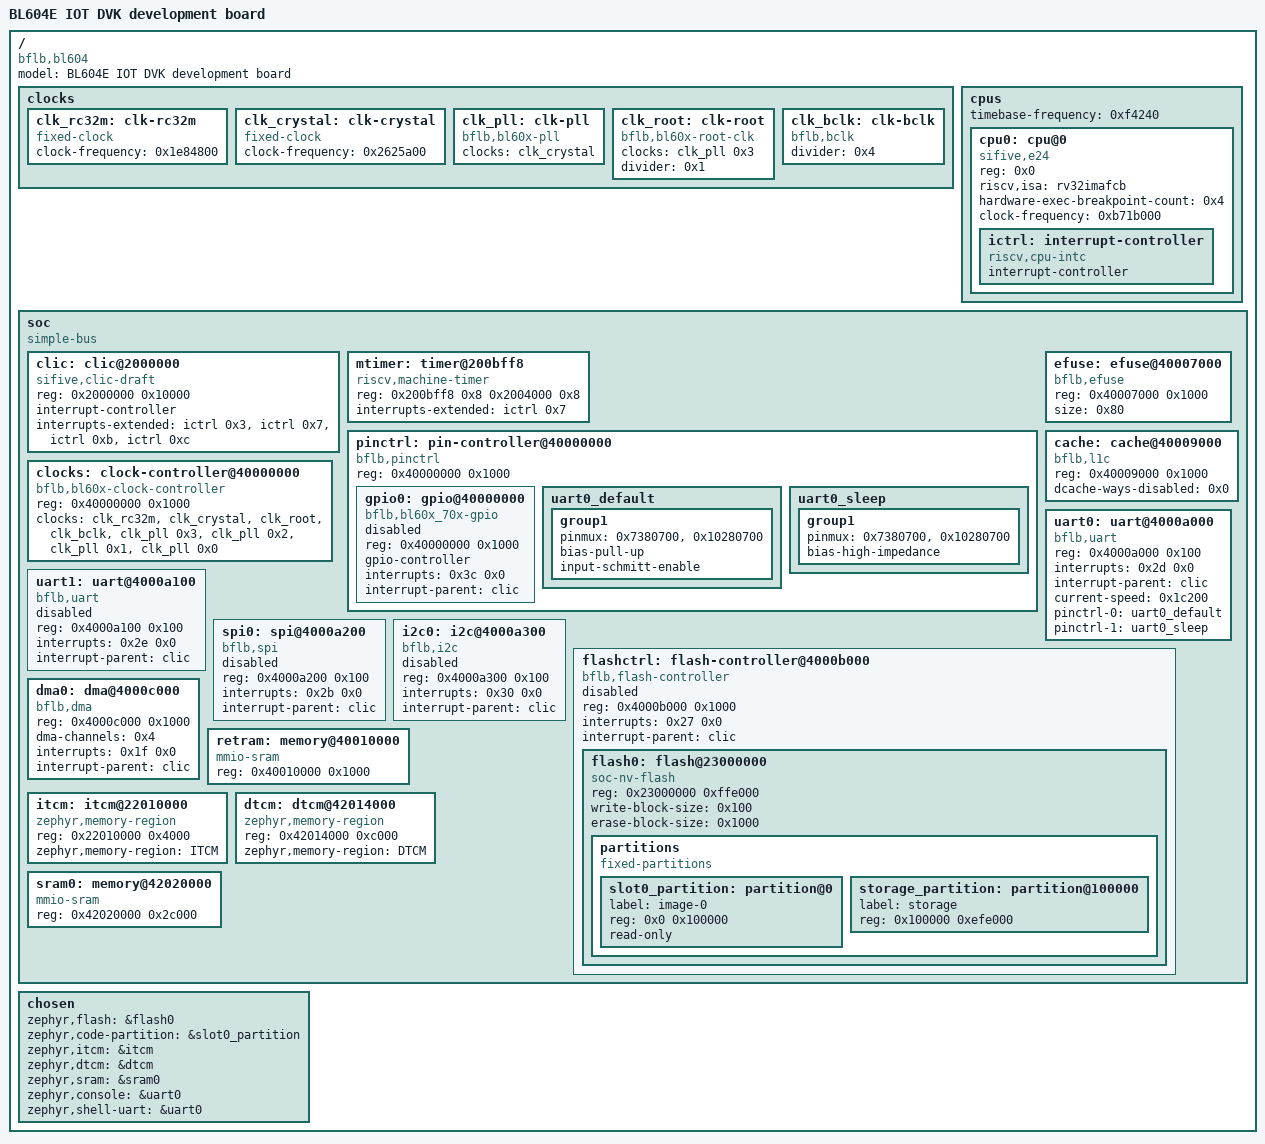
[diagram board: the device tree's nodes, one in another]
/dts-v1/;

/* node '/' defined in zephyr/dts/riscv/bflb/bl60x.dtsi:15 */
/ {
	#address-cells = < 0x1 >;                   /* in zephyr/dts/riscv/bflb/bl60x.dtsi:16 */
	#size-cells = < 0x1 >;                      /* in zephyr/dts/riscv/bflb/bl60x.dtsi:17 */
	model = "BL604E IOT DVK development board"; /* in zephyr/boards/bflb/bl60x/bl604e_iot_dvk/bl604e_iot_dvk.dts:13 */
	compatible = "bflb,bl604";                  /* in zephyr/boards/bflb/bl60x/bl604e_iot_dvk/bl604e_iot_dvk.dts:14 */

	/* node '/clocks' defined in zephyr/dts/riscv/bflb/bl60x.dtsi:19 */
	clocks {

		/* node '/clocks/clk-rc32m' defined in zephyr/dts/riscv/bflb/bl60x.dtsi:20 */
		clk_rc32m: clk-rc32m {
			#clock-cells = < 0x0 >;          /* in zephyr/dts/riscv/bflb/bl60x.dtsi:21 */
			compatible = "fixed-clock";      /* in zephyr/dts/riscv/bflb/bl60x.dtsi:22 */
			clock-frequency = < 0x1e84800 >; /* in zephyr/dts/riscv/bflb/bl60x.dtsi:23 */
			status = "okay";                 /* in zephyr/dts/riscv/bflb/bl60x.dtsi:24 */
			phandle = < 0x5 >;               /* in zephyr/dts/riscv/bflb/bl60x.dtsi:132 */
		};

		/* node '/clocks/clk-crystal' defined in zephyr/dts/riscv/bflb/bl60x.dtsi:27 */
		clk_crystal: clk-crystal {
			#clock-cells = < 0x0 >;          /* in zephyr/dts/riscv/bflb/bl60x.dtsi:28 */
			compatible = "fixed-clock";      /* in zephyr/dts/riscv/bflb/bl60x.dtsi:29 */
			clock-frequency = < 0x2625a00 >; /* in zephyr/dts/riscv/bflb/bl60x.dtsi:30 */
			status = "okay";                 /* in zephyr/dts/riscv/bflb/bl60x.dtsi:31 */
			phandle = < 0x1 >;               /* in zephyr/dts/riscv/bflb/bl60x.dtsi:37 */
		};

		/* node '/clocks/clk-pll' defined in zephyr/dts/riscv/bflb/bl60x.dtsi:34 */
		clk_pll: clk-pll {
			#clock-cells = < 0x1 >;        /* in zephyr/dts/riscv/bflb/bl60x.dtsi:35 */
			compatible = "bflb,bl60x-pll"; /* in zephyr/dts/riscv/bflb/bl60x.dtsi:36 */
			clocks = < &clk_crystal >;     /* in zephyr/dts/riscv/bflb/bl60x.dtsi:37 */
			status = "okay";               /* in zephyr/dts/riscv/bflb/bl60x.dtsi:38 */
			phandle = < 0x2 >;             /* in zephyr/dts/riscv/bflb/bl60x.dtsi:44 */
		};

		/* node '/clocks/clk-root' defined in zephyr/dts/riscv/bflb/bl60x.dtsi:41 */
		clk_root: clk-root {
			#clock-cells = < 0x0 >;             /* in zephyr/dts/riscv/bflb/bl60x.dtsi:42 */
			compatible = "bflb,bl60x-root-clk"; /* in zephyr/dts/riscv/bflb/bl60x.dtsi:43 */
			clocks = < &clk_pll 0x3 >;          /* in zephyr/dts/riscv/bflb/bl60x.dtsi:44 */
			divider = < 0x1 >;                  /* in zephyr/dts/riscv/bflb/bl60x.dtsi:45 */
			status = "okay";                    /* in zephyr/dts/riscv/bflb/bl60x.dtsi:46 */
			phandle = < 0x6 >;                  /* in zephyr/dts/riscv/bflb/bl60x.dtsi:132 */
		};

		/* node '/clocks/clk-bclk' defined in zephyr/dts/riscv/bflb/bl60x.dtsi:49 */
		clk_bclk: clk-bclk {
			#clock-cells = < 0x0 >;   /* in zephyr/dts/riscv/bflb/bl60x.dtsi:50 */
			compatible = "bflb,bclk"; /* in zephyr/dts/riscv/bflb/bl60x.dtsi:51 */
			divider = < 0x4 >;        /* in zephyr/dts/riscv/bflb/bl60x.dtsi:52 */
			status = "okay";          /* in zephyr/dts/riscv/bflb/bl60x.dtsi:53 */
			phandle = < 0x7 >;        /* in zephyr/dts/riscv/bflb/bl60x.dtsi:132 */
		};
	};

	/* node '/cpus' defined in zephyr/dts/riscv/bflb/bl60x.dtsi:57 */
	cpus {
		#address-cells = < 0x1 >;         /* in zephyr/dts/riscv/bflb/bl60x.dtsi:58 */
		#size-cells = < 0x0 >;            /* in zephyr/dts/riscv/bflb/bl60x.dtsi:59 */
		timebase-frequency = < 0xf4240 >; /* in zephyr/dts/riscv/bflb/bl60x.dtsi:60 */

		/* node '/cpus/cpu@0' defined in zephyr/dts/riscv/bflb/bl60x.dtsi:62 */
		cpu0: cpu@0 {
			device_type = "cpu";                      /* in zephyr/dts/riscv/bflb/bl60x.dtsi:63 */
			compatible = "sifive,e24",
			             "riscv";                     /* in zephyr/dts/riscv/bflb/bl60x.dtsi:64 */
			reg = < 0x0 >;                            /* in zephyr/dts/riscv/bflb/bl60x.dtsi:65 */
			riscv,isa = "rv32imafcb";                 /* in zephyr/dts/riscv/bflb/bl60x.dtsi:66 */
			hardware-exec-breakpoint-count = < 0x4 >; /* in zephyr/dts/riscv/bflb/bl60x.dtsi:67 */
			status = "okay";                          /* in zephyr/dts/riscv/bflb/bl60x.dtsi:68 */
			clock-frequency = < 0xb71b000 >;          /* in zephyr/boards/bflb/bl60x/bl604e_iot_dvk/bl604e_iot_dvk.dts:28 */

			/* node '/cpus/cpu@0/interrupt-controller' defined in zephyr/dts/riscv/bflb/bl60x.dtsi:70 */
			ictrl: interrupt-controller {
				#address-cells = < 0x0 >;      /* in zephyr/dts/riscv/bflb/bl60x.dtsi:71 */
				#interrupt-cells = < 0x1 >;    /* in zephyr/dts/riscv/bflb/bl60x.dtsi:72 */
				compatible = "riscv,cpu-intc"; /* in zephyr/dts/riscv/bflb/bl60x.dtsi:73 */
				interrupt-controller;          /* in zephyr/dts/riscv/bflb/bl60x.dtsi:74 */
				phandle = < 0x3 >;             /* in zephyr/dts/riscv/bflb/bl60x.dtsi:92 */
			};
		};
	};

	/* node '/soc' defined in zephyr/dts/riscv/bflb/bl60x.dtsi:79 */
	soc {
		compatible = "simple-bus"; /* in zephyr/dts/riscv/bflb/bl60x.dtsi:80 */
		#address-cells = < 0x1 >;  /* in zephyr/dts/riscv/bflb/bl60x.dtsi:81 */
		#size-cells = < 0x1 >;     /* in zephyr/dts/riscv/bflb/bl60x.dtsi:82 */
		ranges;                    /* in zephyr/dts/riscv/bflb/bl60x.dtsi:83 */

		/* node '/soc/clic@2000000' defined in zephyr/dts/riscv/bflb/bl60x.dtsi:85 */
		clic: clic@2000000 {
			compatible = "sifive,clic-draft";                                      /* in zephyr/dts/riscv/bflb/bl60x.dtsi:86 */
			reg = < 0x2000000 0x10000 >;                                           /* in zephyr/dts/riscv/bflb/bl60x.dtsi:87 */
			#address-cells = < 0x0 >;                                              /* in zephyr/dts/riscv/bflb/bl60x.dtsi:88 */
			#interrupt-cells = < 0x2 >;                                            /* in zephyr/dts/riscv/bflb/bl60x.dtsi:89 */
			interrupt-controller;                                                  /* in zephyr/dts/riscv/bflb/bl60x.dtsi:91 */
			interrupts-extended = < &ictrl 0x3 &ictrl 0x7 &ictrl 0xb &ictrl 0xc >; /* in zephyr/dts/riscv/bflb/bl60x.dtsi:92 */
			interrupt-names = "msip",
			                  "mtip",
			                  "meip",
			                  "csip";                                              /* in zephyr/dts/riscv/bflb/bl60x.dtsi:93 */
			phandle = < 0x4 >;                                                     /* in zephyr/dts/riscv/bflb/bl60x.dtsi:123 */
		};

		/* node '/soc/timer@200bff8' defined in zephyr/dts/riscv/bflb/bl60x.dtsi:99 */
		mtimer: timer@200bff8 {
			compatible = "riscv,machine-timer";    /* in zephyr/dts/riscv/bflb/bl60x.dtsi:100 */
			reg = < 0x200bff8 0x8 0x2004000 0x8 >; /* in zephyr/dts/riscv/bflb/bl60x.dtsi:101 */
			reg-names = "mtime",
			            "mtimecmp";                /* in zephyr/dts/riscv/bflb/bl60x.dtsi:102 */
			interrupts-extended = < &ictrl 0x7 >;  /* in zephyr/dts/riscv/bflb/bl60x.dtsi:104 */
		};

		/* node '/soc/pin-controller@40000000' defined in zephyr/dts/riscv/bflb/bl60x.dtsi:107 */
		pinctrl: pin-controller@40000000 {
			compatible = "bflb,pinctrl";               /* in zephyr/dts/riscv/bflb/bl60x.dtsi:108 */
			reg = < 0x40000000 0x1000 >;               /* in zephyr/dts/riscv/bflb/bl60x.dtsi:109 */
			ranges = < 0x40000000 0x40000000 0x1000 >; /* in zephyr/dts/riscv/bflb/bl60x.dtsi:110 */
			#address-cells = < 0x1 >;                  /* in zephyr/dts/riscv/bflb/bl60x.dtsi:111 */
			#size-cells = < 0x1 >;                     /* in zephyr/dts/riscv/bflb/bl60x.dtsi:112 */
			status = "okay";                           /* in zephyr/dts/riscv/bflb/bl60x.dtsi:113 */

			/* node '/soc/pin-controller@40000000/gpio@40000000' defined in zephyr/dts/riscv/bflb/bl60x.dtsi:115 */
			gpio0: gpio@40000000 {
				compatible = "bflb,bl60x_70x-gpio"; /* in zephyr/dts/riscv/bflb/bl60x.dtsi:116 */
				reg = < 0x40000000 0x1000 >;        /* in zephyr/dts/riscv/bflb/bl60x.dtsi:117 */
				#gpio-cells = < 0x2 >;              /* in zephyr/dts/riscv/bflb/bl60x.dtsi:118 */
				status = "disabled";                /* in zephyr/dts/riscv/bflb/bl60x.dtsi:119 */
				gpio-controller;                    /* in zephyr/dts/riscv/bflb/bl60x.dtsi:121 */
				interrupts = < 0x3c 0x0 >;          /* in zephyr/dts/riscv/bflb/bl60x.dtsi:122 */
				interrupt-parent = < &clic >;       /* in zephyr/dts/riscv/bflb/bl60x.dtsi:123 */
			};

			/* node '/soc/pin-controller@40000000/uart0_default' defined in zephyr/boards/bflb/bl60x/bl604e_iot_dvk/bl604e_iot_dvk-pinctrl.dtsi:10 */
			uart0_default: uart0_default {
				phandle = < 0x8 >; /* in zephyr/boards/bflb/bl60x/bl604e_iot_dvk/bl604e_iot_dvk.dts:62 */

				/* node '/soc/pin-controller@40000000/uart0_default/group1' defined in zephyr/boards/bflb/bl60x/bl604e_iot_dvk/bl604e_iot_dvk-pinctrl.dtsi:11 */
				group1 {
					pinmux = < 0x7380700 >,
					         < 0x10280700 >; /* in zephyr/boards/bflb/bl60x/bl604e_iot_dvk/bl604e_iot_dvk-pinctrl.dtsi:12 */
					bias-pull-up;            /* in zephyr/boards/bflb/bl60x/bl604e_iot_dvk/bl604e_iot_dvk-pinctrl.dtsi:14 */
					input-schmitt-enable;    /* in zephyr/boards/bflb/bl60x/bl604e_iot_dvk/bl604e_iot_dvk-pinctrl.dtsi:15 */
				};
			};

			/* node '/soc/pin-controller@40000000/uart0_sleep' defined in zephyr/boards/bflb/bl60x/bl604e_iot_dvk/bl604e_iot_dvk-pinctrl.dtsi:19 */
			uart0_sleep: uart0_sleep {
				phandle = < 0x9 >; /* in zephyr/boards/bflb/bl60x/bl604e_iot_dvk/bl604e_iot_dvk.dts:63 */

				/* node '/soc/pin-controller@40000000/uart0_sleep/group1' defined in zephyr/boards/bflb/bl60x/bl604e_iot_dvk/bl604e_iot_dvk-pinctrl.dtsi:20 */
				group1 {
					pinmux = < 0x7380700 >,
					         < 0x10280700 >; /* in zephyr/boards/bflb/bl60x/bl604e_iot_dvk/bl604e_iot_dvk-pinctrl.dtsi:21 */
					bias-high-impedance;     /* in zephyr/boards/bflb/bl60x/bl604e_iot_dvk/bl604e_iot_dvk-pinctrl.dtsi:23 */
				};
			};
		};

		/* node '/soc/clock-controller@40000000' defined in zephyr/dts/riscv/bflb/bl60x.dtsi:127 */
		clocks: clock-controller@40000000 {
			compatible = "bflb,bl60x-clock-controller",
			             "bflb,clock-controller";       /* in zephyr/dts/riscv/bflb/bl60x.dtsi:128 */
			reg = < 0x40000000 0x1000 >;                /* in zephyr/dts/riscv/bflb/bl60x.dtsi:129 */
			#clock-cells = < 0x1 >;                     /* in zephyr/dts/riscv/bflb/bl60x.dtsi:130 */
			status = "okay";                            /* in zephyr/dts/riscv/bflb/bl60x.dtsi:131 */
			clocks = < &clk_rc32m >,
			         < &clk_crystal >,
			         < &clk_root >,
			         < &clk_bclk >,
			         < &clk_pll 0x3 >,
			         < &clk_pll 0x2 >,
			         < &clk_pll 0x1 >,
			         < &clk_pll 0x0 >;                  /* in zephyr/dts/riscv/bflb/bl60x.dtsi:132 */
			clock-names = "rc32m",
			              "crystal",
			              "root",
			              "bclk",
			              "pll_192",
			              "pll_160",
			              "pll_120",
			              "pll_48";                     /* in zephyr/dts/riscv/bflb/bl60x.dtsi:135 */
		};

		/* node '/soc/efuse@40007000' defined in zephyr/dts/riscv/bflb/bl60x.dtsi:140 */
		efuse: efuse@40007000 {
			compatible = "bflb,efuse";   /* in zephyr/dts/riscv/bflb/bl60x.dtsi:141 */
			reg = < 0x40007000 0x1000 >; /* in zephyr/dts/riscv/bflb/bl60x.dtsi:142 */
			status = "okay";             /* in zephyr/dts/riscv/bflb/bl60x.dtsi:143 */
			size = < 0x80 >;             /* in zephyr/dts/riscv/bflb/bl60x.dtsi:144 */
		};

		/* node '/soc/cache@40009000' defined in zephyr/dts/riscv/bflb/bl60x.dtsi:147 */
		cache: cache@40009000 {
			reg = < 0x40009000 0x1000 >;    /* in zephyr/dts/riscv/bflb/bl60x.dtsi:148 */
			compatible = "bflb,l1c";        /* in zephyr/dts/riscv/bflb/bl60x.dtsi:149 */
			dcache-ways-disabled = < 0x0 >; /* in zephyr/dts/riscv/bflb/bl60x.dtsi:150 */
		};

		/* node '/soc/uart@4000a000' defined in zephyr/dts/riscv/bflb/bl60x.dtsi:153 */
		uart0: uart@4000a000 {
			compatible = "bflb,uart";       /* in zephyr/dts/riscv/bflb/bl60x.dtsi:154 */
			reg = < 0x4000a000 0x100 >;     /* in zephyr/dts/riscv/bflb/bl60x.dtsi:155 */
			interrupts = < 0x2d 0x0 >;      /* in zephyr/dts/riscv/bflb/bl60x.dtsi:156 */
			interrupt-parent = < &clic >;   /* in zephyr/dts/riscv/bflb/bl60x.dtsi:157 */
			status = "okay";                /* in zephyr/boards/bflb/bl60x/bl604e_iot_dvk/bl604e_iot_dvk.dts:59 */
			current-speed = < 0x1c200 >;    /* in zephyr/boards/bflb/bl60x/bl604e_iot_dvk/bl604e_iot_dvk.dts:60 */
			pinctrl-0 = < &uart0_default >; /* in zephyr/boards/bflb/bl60x/bl604e_iot_dvk/bl604e_iot_dvk.dts:62 */
			pinctrl-1 = < &uart0_sleep >;   /* in zephyr/boards/bflb/bl60x/bl604e_iot_dvk/bl604e_iot_dvk.dts:63 */
			pinctrl-names = "default",
			                "sleep";        /* in zephyr/boards/bflb/bl60x/bl604e_iot_dvk/bl604e_iot_dvk.dts:64 */
		};

		/* node '/soc/uart@4000a100' defined in zephyr/dts/riscv/bflb/bl60x.dtsi:161 */
		uart1: uart@4000a100 {
			compatible = "bflb,uart";     /* in zephyr/dts/riscv/bflb/bl60x.dtsi:162 */
			reg = < 0x4000a100 0x100 >;   /* in zephyr/dts/riscv/bflb/bl60x.dtsi:163 */
			interrupts = < 0x2e 0x0 >;    /* in zephyr/dts/riscv/bflb/bl60x.dtsi:164 */
			interrupt-parent = < &clic >; /* in zephyr/dts/riscv/bflb/bl60x.dtsi:165 */
			status = "disabled";          /* in zephyr/dts/riscv/bflb/bl60x.dtsi:166 */
		};

		/* node '/soc/spi@4000a200' defined in zephyr/dts/riscv/bflb/bl60x.dtsi:169 */
		spi0: spi@4000a200 {
			compatible = "bflb,spi";      /* in zephyr/dts/riscv/bflb/bl60x.dtsi:170 */
			reg = < 0x4000a200 0x100 >;   /* in zephyr/dts/riscv/bflb/bl60x.dtsi:171 */
			#address-cells = < 0x1 >;     /* in zephyr/dts/riscv/bflb/bl60x.dtsi:172 */
			#size-cells = < 0x0 >;        /* in zephyr/dts/riscv/bflb/bl60x.dtsi:173 */
			status = "disabled";          /* in zephyr/dts/riscv/bflb/bl60x.dtsi:174 */
			interrupts = < 0x2b 0x0 >;    /* in zephyr/dts/riscv/bflb/bl60x.dtsi:176 */
			interrupt-parent = < &clic >; /* in zephyr/dts/riscv/bflb/bl60x.dtsi:177 */
		};

		/* node '/soc/i2c@4000a300' defined in zephyr/dts/riscv/bflb/bl60x.dtsi:180 */
		i2c0: i2c@4000a300 {
			compatible = "bflb,i2c";      /* in zephyr/dts/riscv/bflb/bl60x.dtsi:181 */
			reg = < 0x4000a300 0x100 >;   /* in zephyr/dts/riscv/bflb/bl60x.dtsi:182 */
			#address-cells = < 0x1 >;     /* in zephyr/dts/riscv/bflb/bl60x.dtsi:183 */
			#size-cells = < 0x0 >;        /* in zephyr/dts/riscv/bflb/bl60x.dtsi:184 */
			status = "disabled";          /* in zephyr/dts/riscv/bflb/bl60x.dtsi:185 */
			interrupts = < 0x30 0x0 >;    /* in zephyr/dts/riscv/bflb/bl60x.dtsi:187 */
			interrupt-parent = < &clic >; /* in zephyr/dts/riscv/bflb/bl60x.dtsi:188 */
		};

		/* node '/soc/flash-controller@4000b000' defined in zephyr/dts/riscv/bflb/bl60x.dtsi:191 */
		flashctrl: flash-controller@4000b000 {
			compatible = "bflb,flash-controller"; /* in zephyr/dts/riscv/bflb/bl60x.dtsi:192 */
			reg = < 0x4000b000 0x1000 >;          /* in zephyr/dts/riscv/bflb/bl60x.dtsi:193 */
			#address-cells = < 0x1 >;             /* in zephyr/dts/riscv/bflb/bl60x.dtsi:194 */
			#size-cells = < 0x1 >;                /* in zephyr/dts/riscv/bflb/bl60x.dtsi:195 */
			status = "disabled";                  /* in zephyr/dts/riscv/bflb/bl60x.dtsi:196 */
			interrupts = < 0x27 0x0 >;            /* in zephyr/dts/riscv/bflb/bl60x.dtsi:198 */
			interrupt-parent = < &clic >;         /* in zephyr/dts/riscv/bflb/bl60x.dtsi:199 */

			/* node '/soc/flash-controller@4000b000/flash@23000000' defined in zephyr/boards/bflb/bl60x/bl604e_iot_dvk/bl604e_iot_dvk.dts:32 */
			flash0: flash@23000000 {
				compatible = "soc-nv-flash",
				             "issi,is25lp128"; /* in zephyr/boards/bflb/bl60x/bl604e_iot_dvk/bl604e_iot_dvk.dts:33 */
				reg = < 0x23000000 0xffe000 >; /* in zephyr/boards/bflb/bl60x/bl604e_iot_dvk/bl604e_iot_dvk.dts:34 */
				write-block-size = < 0x100 >;  /* in zephyr/boards/bflb/bl60x/bl604e_iot_dvk/bl604e_iot_dvk.dts:35 */
				erase-block-size = < 0x1000 >; /* in zephyr/boards/bflb/bl60x/bl604e_iot_dvk/bl604e_iot_dvk.dts:36 */

				/* node '/soc/flash-controller@4000b000/flash@23000000/partitions' defined in zephyr/boards/bflb/bl60x/bl604e_iot_dvk/bl604e_iot_dvk.dts:39 */
				partitions {
					compatible = "fixed-partitions"; /* in zephyr/boards/bflb/bl60x/bl604e_iot_dvk/bl604e_iot_dvk.dts:40 */
					#address-cells = < 0x1 >;        /* in zephyr/boards/bflb/bl60x/bl604e_iot_dvk/bl604e_iot_dvk.dts:41 */
					#size-cells = < 0x1 >;           /* in zephyr/boards/bflb/bl60x/bl604e_iot_dvk/bl604e_iot_dvk.dts:42 */

					/* node '/soc/flash-controller@4000b000/flash@23000000/partitions/partition@0' defined in zephyr/boards/bflb/bl60x/bl604e_iot_dvk/bl604e_iot_dvk.dts:44 */
					slot0_partition: partition@0 {
						label = "image-0";      /* in zephyr/boards/bflb/bl60x/bl604e_iot_dvk/bl604e_iot_dvk.dts:45 */
						reg = < 0x0 0x100000 >; /* in zephyr/boards/bflb/bl60x/bl604e_iot_dvk/bl604e_iot_dvk.dts:46 */
						read-only;              /* in zephyr/boards/bflb/bl60x/bl604e_iot_dvk/bl604e_iot_dvk.dts:47 */
					};

					/* node '/soc/flash-controller@4000b000/flash@23000000/partitions/partition@100000' defined in zephyr/boards/bflb/bl60x/bl604e_iot_dvk/bl604e_iot_dvk.dts:50 */
					storage_partition: partition@100000 {
						label = "storage";           /* in zephyr/boards/bflb/bl60x/bl604e_iot_dvk/bl604e_iot_dvk.dts:51 */
						reg = < 0x100000 0xefe000 >; /* in zephyr/boards/bflb/bl60x/bl604e_iot_dvk/bl604e_iot_dvk.dts:52 */
					};
				};
			};
		};

		/* node '/soc/dma@4000c000' defined in zephyr/dts/riscv/bflb/bl60x.dtsi:202 */
		dma0: dma@4000c000 {
			compatible = "bflb,dma";      /* in zephyr/dts/riscv/bflb/bl60x.dtsi:203 */
			reg = < 0x4000c000 0x1000 >;  /* in zephyr/dts/riscv/bflb/bl60x.dtsi:204 */
			#dma-cells = < 0x1 >;         /* in zephyr/dts/riscv/bflb/bl60x.dtsi:205 */
			dma-channels = < 0x4 >;       /* in zephyr/dts/riscv/bflb/bl60x.dtsi:206 */
			interrupts = < 0x1f 0x0 >;    /* in zephyr/dts/riscv/bflb/bl60x.dtsi:208 */
			interrupt-parent = < &clic >; /* in zephyr/dts/riscv/bflb/bl60x.dtsi:209 */
		};

		/* node '/soc/memory@40010000' defined in zephyr/dts/riscv/bflb/bl60x.dtsi:212 */
		retram: memory@40010000 {
			compatible = "mmio-sram";    /* in zephyr/dts/riscv/bflb/bl60x.dtsi:213 */
			reg = < 0x40010000 0x1000 >; /* in zephyr/dts/riscv/bflb/bl60x.dtsi:214 */
		};

		/* node '/soc/itcm@22010000' defined in zephyr/dts/riscv/bflb/bl60x.dtsi:217 */
		itcm: itcm@22010000 {
			compatible = "zephyr,memory-region",
			             "sifive,dtim0";         /* in zephyr/dts/riscv/bflb/bl60x.dtsi:218 */
			reg = < 0x22010000 0x4000 >;         /* in zephyr/dts/riscv/bflb/bl60x.dtsi:219 */
			zephyr,memory-region = "ITCM";       /* in zephyr/dts/riscv/bflb/bl60x.dtsi:220 */
		};

		/* node '/soc/dtcm@42014000' defined in zephyr/dts/riscv/bflb/bl60x.dtsi:223 */
		dtcm: dtcm@42014000 {
			compatible = "zephyr,memory-region",
			             "sifive,dtim0";         /* in zephyr/dts/riscv/bflb/bl60x.dtsi:224 */
			reg = < 0x42014000 0xc000 >;         /* in zephyr/dts/riscv/bflb/bl60x.dtsi:225 */
			zephyr,memory-region = "DTCM";       /* in zephyr/dts/riscv/bflb/bl60x.dtsi:226 */
		};

		/* node '/soc/memory@42020000' defined in zephyr/dts/riscv/bflb/bl60x.dtsi:229 */
		sram0: memory@42020000 {
			compatible = "mmio-sram";     /* in zephyr/dts/riscv/bflb/bl60x.dtsi:230 */
			reg = < 0x42020000 0x2c000 >; /* in zephyr/dts/riscv/bflb/bl60x.dtsi:231 */
		};
	};

	/* node '/chosen' defined in zephyr/boards/bflb/bl60x/bl604e_iot_dvk/bl604e_iot_dvk.dts:16 */
	chosen {
		zephyr,flash = &flash0;                   /* in zephyr/boards/bflb/bl60x/bl604e_iot_dvk/bl604e_iot_dvk.dts:17 */
		zephyr,code-partition = &slot0_partition; /* in zephyr/boards/bflb/bl60x/bl604e_iot_dvk/bl604e_iot_dvk.dts:18 */
		zephyr,itcm = &itcm;                      /* in zephyr/boards/bflb/bl60x/bl604e_iot_dvk/bl604e_iot_dvk.dts:19 */
		zephyr,dtcm = &dtcm;                      /* in zephyr/boards/bflb/bl60x/bl604e_iot_dvk/bl604e_iot_dvk.dts:20 */
		zephyr,sram = &sram0;                     /* in zephyr/boards/bflb/bl60x/bl604e_iot_dvk/bl604e_iot_dvk.dts:21 */
		zephyr,console = &uart0;                  /* in zephyr/boards/bflb/bl60x/bl604e_iot_dvk/bl604e_iot_dvk.dts:22 */
		zephyr,shell-uart = &uart0;               /* in zephyr/boards/bflb/bl60x/bl604e_iot_dvk/bl604e_iot_dvk.dts:23 */
	};
};
